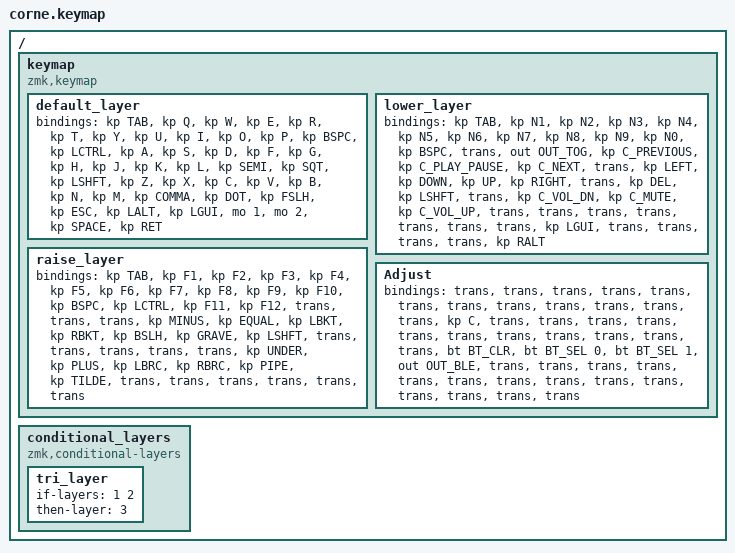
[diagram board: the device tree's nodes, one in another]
/*
 * Copyright (c) 2020 The ZMK Contributors
 *
 * SPDX-License-Identifier: MIT
 */

#include <behaviors.dtsi>
#include <dt-bindings/zmk/bt.h>
#include <dt-bindings/zmk/keys.h>
#include <dt-bindings/zmk/outputs.h>

/ {
    keymap {
        compatible = "zmk,keymap";

        default_layer {
            // -----------------------------------------------------------------------------------------
            // |  TAB |  Q  |  W  |  E  |  R  |  T  |   |  Y  |  U   |  I  |  O  |  P  | BKSP |
            // | CTRL |  A  |  S  |  D  |  F  |  G  |   |  H  |  J   |  K  |  L  |  ;  |  '   |
            // | SHFT |  Z  |  X  |  C  |  V  |  B  |   |  N  |  M   |  ,  |  .  |  /  | ESC  |
            //                    | LALT | GUI | LWR |   | RSE | SPC  | ENT |

            bindings = <
&kp TAB  &kp Q  &kp W  &kp E  &kp R  &kp T  &kp Y  &kp U  &kp I  &kp O  &kp P  &kp BSPC  &kp LCTRL  &kp A  &kp S  &kp D  &kp F  &kp G  &kp H  &kp J  &kp K  &kp L  &kp SEMI  &kp SQT  &kp LSHFT  &kp Z  &kp X  &kp C  &kp V  &kp B  &kp N  &kp M  &kp COMMA  &kp DOT  &kp FSLH  &kp ESC  &kp LALT  &kp LGUI  &mo 1  &mo 2  &kp SPACE  &kp RET
            >;
        };

        lower_layer {
            // -----------------------------------------------------------------------------------------
            // |  TAB |  1  |  2  |  3  |  4  |  5  |   |  6  |  7  |  8  |  9  |  0  | BKSP |
            // | BTCLR| BT1 | BT2 | BT3 | BT4 | BT5 |   | LFT | DWN |  UP | RGT |     |      |
            // | SHFT |     |     |     |     |     |   |     |     |     |     |     |      |
            //                    | GUI |     | SPC |   | ENT |     | ALT |

            bindings = <
&kp TAB  &kp N1  &kp N2  &kp N3  &kp N4  &kp N5  &kp N6  &kp N7  &kp N8  &kp N9  &kp N0  &kp BSPC  &trans  &out OUT_TOG  &kp C_PREVIOUS  &kp C_PLAY_PAUSE  &kp C_NEXT  &trans  &kp LEFT  &kp DOWN  &kp UP  &kp RIGHT  &trans  &kp DEL  &kp LSHFT  &trans  &kp C_VOL_DN  &kp C_MUTE  &kp C_VOL_UP  &trans  &trans  &trans  &trans  &trans  &trans  &trans  &kp LGUI  &trans  &trans  &trans  &trans  &kp RALT
            >;
        };

        raise_layer {
            // -----------------------------------------------------------------------------------------
            // |  TAB |  !  |  @  |  #  |  $  |  %  |   |  ^  |  &  |  *  |  (  |  )  | BKSP |
            // | CTRL |     |     |     |     |     |   |  -  |  =  |  [  |  ]  |  \  |  `   |
            // | SHFT |     |     |     |     |     |   |  _  |  +  |  {  |  }  | "|" |  ~   |
            //                    | GUI |     | SPC |   | ENT |     | ALT |

            bindings = <
&kp TAB  &kp F1  &kp F2  &kp F3  &kp F4  &kp F5  &kp F6  &kp F7  &kp F8  &kp F9  &kp F10  &kp BSPC  &kp LCTRL  &kp F11  &kp F12  &trans  &trans  &trans  &kp MINUS  &kp EQUAL  &kp LBKT  &kp RBKT  &kp BSLH  &kp GRAVE  &kp LSHFT  &trans  &trans  &trans  &trans  &trans  &kp UNDER  &kp PLUS  &kp LBRC  &kp RBRC  &kp PIPE  &kp TILDE  &trans  &trans  &trans  &trans  &trans  &trans
            >;
        };

        Adjust {
            bindings = <
&trans  &trans  &trans  &trans  &trans  &trans  &trans  &trans  &trans  &trans  &trans  &trans  &kp C  &trans  &trans  &trans  &trans  &trans  &trans  &trans  &trans  &trans  &trans  &trans  &bt BT_CLR  &bt BT_SEL 0  &bt BT_SEL 1  &out OUT_BLE  &trans  &trans  &trans  &trans  &trans  &trans  &trans  &trans  &trans  &trans  &trans  &trans  &trans  &trans
            >;
        };
    };
};

/ {
    conditional_layers {
        compatible = "zmk,conditional-layers";

        tri_layer {
            if-layers = <1 2>;
            then-layer = <3>;
        };
    };
};
